AUTOSAR XML (schema 00048)
package /ComponentTypes
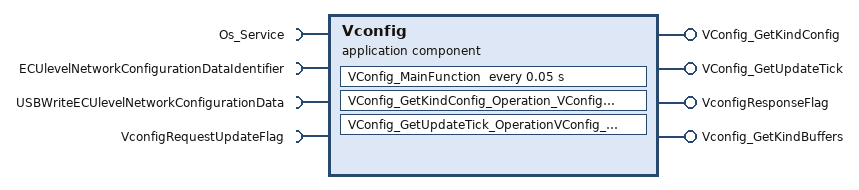
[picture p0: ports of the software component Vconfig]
  application sw component type Vconfig
    provide port VConfig_GetKindConfig: server-com-spec{operation=Operation_VConfig_GetKindConfig, queue-length=1}, provided-interface=VConfig_GetKindConfig
    require port Os_Service: required-com-specs=[GetElapsedValue, GetCounterValue], required-interface=Os_Service
    provide port VConfig_GetUpdateTick: server-com-spec{operation=OperationVConfig_GetUpdateTick, queue-length=1}, provided-interface=VConfig_GetUpdateTick
    require port ECUlevelNetworkConfigurationDataIdentifier: nonqueued-receiver-com-spec{data-element=Element, filter=data-filter-type=ALWAYS, init-value=200 x 0}, required-interface=ECUlevelNetworkConfigurationDataIdentifier
    provide port VconfigResponseFlag: nonqueued-sender-com-spec{data-element=VconfigResponseFlag, init-value=0}, provided-interface=VconfigResponseFlag
    require port USBWriteECUlevelNetworkConfigurationData: client-com-spec=USBWriteData, required-interface=USBWriteECUlevelNetworkConfigurationData
    require port VconfigRequestUpdateFlag: nonqueued-receiver-com-spec{data-element=VconfigRequestUpdateFlag, filter=data-filter-type=ALWAYS, init-value=0}, required-interface=VconfigRequestUpdateFlag
    provide port Vconfig_GetKindBuffers: nonqueued-sender-com-spec{data-element=AllKinds, init-value=600 x 0}, provided-interface=Vconfig_GetKindBuffers
    behavior Vconfig_InternalBehavior
      timing event TMT_Vconfig_MainFunction: start-on-event=VConfig_MainFunction, period=0.05
      operation invoked event OIT_VConfig_GetKindConfig_Operation_VConfig_GetKindConfig_VConfig_GetKindConfig_Operation_VConfig_GetKindConfig: start-on-event=VConfig_GetKindConfig_Operation_VConfig_GetKindConfig, operation=VConfig_GetKindConfig.Operation_VConfig_GetKindConfig
      operation invoked event OIT_VConfig_GetUpdateTick_OperationVConfig_GetUpdateTick_VConfig_GetUpdateTick_OperationVConfig_GetUpdateTick: start-on-event=VConfig_GetUpdateTick_OperationVConfig_GetUpdateTick, operation=VConfig_GetUpdateTick.OperationVConfig_GetUpdateTick
      runnable VConfig_MainFunction
        data-receive-point-by-arguments:
          access REC_ECUlevelNetworkConfigurationDataIdentifier_Element: accessed-variable=ECUlevelNetworkConfigurationDataIdentifier.Element
          access REC_VconfigRequestUpdateFlag_VconfigRequestUpdateFlag: accessed-variable=VconfigRequestUpdateFlag.VconfigRequestUpdateFlag
        data-send-points:
          access SEND_VconfigResponseFlag_VconfigResponseFlag: accessed-variable=VconfigResponseFlag.VconfigResponseFlag
          access SEND_Vconfig_GetKindBuffers_Kind600Bytes: accessed-variable=Vconfig_GetKindBuffers.AllKinds
        sync call SC_Os_Service_GetCounterValue: operation=Os_Service.GetCounterValue
        sync call SC_USBWriteECUlevelNetworkConfigurationData_USBWriteData: operation=USBWriteECUlevelNetworkConfigurationData.USBWriteData
      runnable VConfig_GetKindConfig_Operation_VConfig_GetKindConfig
      runnable VConfig_GetUpdateTick_OperationVConfig_GetUpdateTick
  swc implementation Vconfig_Implementation: behavior=Vconfig_InternalBehavior
